# pse84 register map
Vendor: Cypress Semiconductor; Series: PSE84; File version: 1.0
CPU: CM33 r0p1, little endian, MPU, FPU, VTOR, 3 interrupt priority bits
Registers are 32-bit, read-write, reset 0x0 unless marked. A register's access mark holds for its fields unless they carry their own. Offsets are from the block's base; [hi:lo] are bit positions; lines under a group give offsets from that group; {n}, {i} and the like mark numbered series.

## APPCPUSS_SL_CTL — APPCPUSS Internal slave control registers
Base 0x441C8000
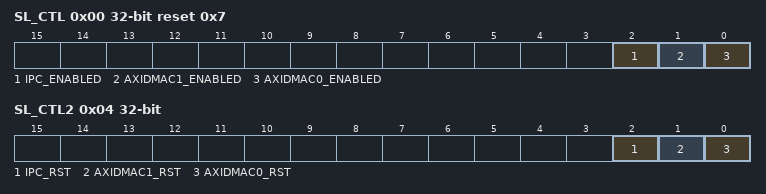
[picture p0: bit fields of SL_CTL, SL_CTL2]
0x00 SL_CTL reset 0x7 — Slave control (Clock enables)
  [2] IPC_ENABLED — 0: IPC disabled 1: IPC enabled
  [1] AXIDMAC1_ENABLED — 0: AXI DMAC1 disabled 1: AXI DMAC1 enabled
  [0] AXIDMAC0_ENABLED — Slave enable controls. Each bit indicates whether the respective slave is enabled or not. 0: Disabled 1: Enabled If the slave is disabled, its clock is gated off (constant '0'). Any access (MMIO AHB access) to slave when disabled result in AHB error response.
0x04 SL_CTL2 — Slave control2 (Reset enables)
  [2] IPC_RST — 0: IPC reset disabled 1: IPC reset enabled
  [1] AXIDMAC1_RST — 0: AXI DMAC1 reset disabled 1: AXI DMAC1 reset enabled
  [0] AXIDMAC0_RST — Slave reset controls. Each bit indicates whether the respective slave reset is enabled or not. 0: Disabled 1: Enabled If the slave is under reset enabled state, its clock is gated off (constant '0') and its resets are in activated state (rst_n = 0) Any access (MMIO AHB access) to slave when disabled result in AHB error response.

## SDHC0 (part 3 of 3) — SD/eMMC Host Controller
Base 0x44810000
Same registers: SDHC1 0x44820000
0x00 WRAP group — MMIO at SDHC wrapper level
  0x00 CTL — Top level wrapper control
    [31] ENABLE — IP Enable: 0: IP disabled, RAM in DeepSleep, SDHC_CORE regs are inaccessible (any attempts to access will result in AHB Error responses), IP is NOT held in reset but the clocks are gated 1: IP enabled, normal operation

## SYSAP — System debug Access Port (SYSAP) registers
Base 0xE0000000
0xBE000 ROMTABLE group — System Debug Access Port ROM-Table with Cypress Vendor/Silicon ID
  0xFCC DID ro reset 0x1 — Device Type Identifier register.
    [31:0] VALUE
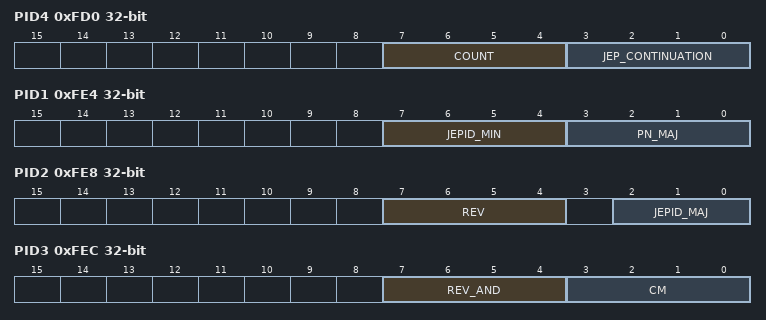
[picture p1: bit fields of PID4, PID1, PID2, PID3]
  0xFD0 PID4 ro (reset mask 0xF0) — Peripheral Identification Register 4.
    [7:4] COUNT — Size of ROM Table is 2^COUNT * 4 KByte.
    [3:0] JEP_CONTINUATION — JEP106 continuation code. This value is product specific and specified as part of the product definition in the CPUSS.JEPCONTINUATION parameter.
  {0xFC0+4j} PID{j} ro (j=5..7) — Peripheral Identification Register {j}.
    [31:0] VALUE
  0xFE0 PID0 ro reset not defined — Peripheral Identification Register 0.
    [7:0] PN_MIN — JEP106 part number. 4 lsbs of CPUSS.PARTNUMBER parameter. These part numbers are maintained in spec 40-9500.
  0xFE4 PID1 ro reset not defined — Peripheral Identification Register 1.
    [7:4] JEPID_MIN — JEP106 vendor id. 4 lsbs of CPUSS.JEPID parameter. This number is maintained in spec 40-9500.
    [3:0] PN_MAJ — JEP106 part number. 4 msbs of CPUSS.PARTNUMBER parameter. These part numbers are maintained in spec 40-9500.
  0xFE8 PID2 ro reset not defined — Peripheral Identification Register 2.
    [7:4] REV — Major REVision number (chip specific). Identifies the design iteration of the component. For first tape out: 0x1. This field is implemented in RTL by an ECO-able tie-off structure and is incremented on subsequent tape outs.
    [2:0] JEPID_MAJ — JEP106 vendor id. 4 msbs of CPUSS.JEPID parameter. This number is maintained in spec 40-9500.
  0xFEC PID3 ro (reset mask 0xF) — Peripheral Identification Register 3.
    [7:4] REV_AND — Minor REVision number (chip specific). For first tape out: 0x1. This field is implemented in RTL by an ECO-able tie-off structure and is incremented on subsequent tape outs.
    [3:0] CM — Customer modified field. This field is used to track modifications to the original component design as a result of component IP reuse.
  0xFF0 CID0 ro reset 0xD — Component Identification Register 0.
    [31:0] VALUE — Component identification byte 0 of 4-byte component identification 0xB105:100D.
  0xFF4 CID1 ro reset 0x10 — Component Identification Register 1.
    [31:0] VALUE — Component identification byte 1 of 4-byte component identification 0xB105:100D. Component class: 'ROM Table'.
  0xFF8 CID2 ro reset 0x5 — Component Identification Register 2.
    [31:0] VALUE — Component identification byte 2 of 4-byte component identification 0xB105:100D.
  0xFFC CID3 ro reset 0xB1 — Component Identification Register 3.
    [31:0] VALUE — Component identification byte 3 of 4-byte component identification 0xB105:100D.
